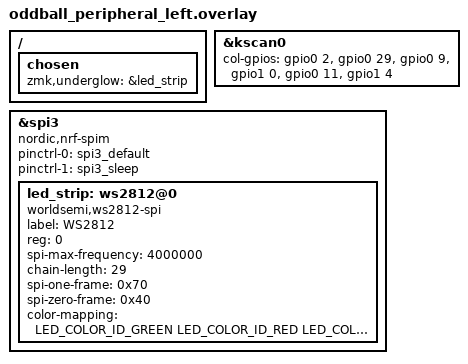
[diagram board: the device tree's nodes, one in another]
/*
 * Copyright (c) 2020 ZMK Contributors
 *
 * SPDX-License-Identifier: MIT
 */

#include "oddball.dtsi"

&kscan0 {
	col-gpios
		= <&gpio0 2 (GPIO_ACTIVE_HIGH | GPIO_PULL_DOWN)>
		, <&gpio0 29 (GPIO_ACTIVE_HIGH | GPIO_PULL_DOWN)>
		, <&gpio0 9 (GPIO_ACTIVE_HIGH | GPIO_PULL_DOWN)>
		, <&gpio1 0  (GPIO_ACTIVE_HIGH | GPIO_PULL_DOWN)>
		, <&gpio0 11 (GPIO_ACTIVE_HIGH | GPIO_PULL_DOWN)>
		, <&gpio1 4  (GPIO_ACTIVE_HIGH | GPIO_PULL_DOWN)>
		;
};
&spi3 {
	compatible = "nordic,nrf-spim";
	status = "okay";

	pinctrl-0 = <&spi3_default>;
	pinctrl-1 = <&spi3_sleep>;
	pinctrl-names = "default", "sleep";


	led_strip: ws2812@0 {
		compatible = "worldsemi,ws2812-spi";
		label = "WS2812";

		/* SPI */
		reg = <0>; /* ignored, but necessary for SPI bindings */
		spi-max-frequency = <4000000>;

		/* WS2812 */
		chain-length = <29>; /* There are per-key RGB, but the first 6 are underglow */
		spi-one-frame = <0x70>;
		spi-zero-frame = <0x40>;
		color-mapping = <LED_COLOR_ID_GREEN LED_COLOR_ID_RED LED_COLOR_ID_BLUE>;
	};
};

/ {
	chosen {
		zmk,underglow = &led_strip;
	};
};
